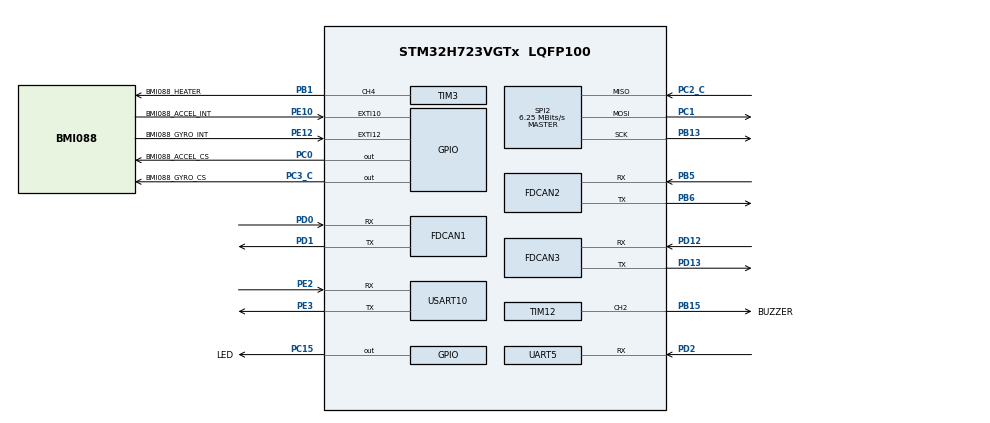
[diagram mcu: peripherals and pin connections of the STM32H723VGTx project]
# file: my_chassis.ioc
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CORTEX_M7.CPU_DCache=Disabled
CORTEX_M7.CPU_ICache=Enabled
CORTEX_M7.MPU_Control=__NULL
CORTEX_M7.default_mode_Activation=1
Dma.Request0=SPI2_TX
Dma.Request1=SPI2_RX
Dma.Request2=USART10_RX
Dma.Request3=USART10_TX
Dma.Request4=UART5_RX
Dma.SPI2_RX.1.Direction=DMA_PERIPH_TO_MEMORY
Dma.SPI2_RX.1.EventEnable=DISABLE
Dma.SPI2_RX.1.FIFOMode=DMA_FIFOMODE_DISABLE
Dma.SPI2_RX.1.Instance=DMA1_Stream1
Dma.SPI2_RX.1.MemDataAlignment=DMA_MDATAALIGN_BYTE
Dma.SPI2_RX.1.MemInc=DMA_MINC_ENABLE
Dma.SPI2_RX.1.Mode=DMA_NORMAL
Dma.SPI2_RX.1.PeriphDataAlignment=DMA_PDATAALIGN_BYTE
Dma.SPI2_RX.1.PeriphInc=DMA_PINC_DISABLE
Dma.SPI2_RX.1.Polarity=HAL_DMAMUX_REQ_GEN_RISING
Dma.SPI2_RX.1.Priority=DMA_PRIORITY_LOW
Dma.SPI2_RX.1.RequestNumber=1
Dma.SPI2_RX.1.SignalID=NONE
Dma.SPI2_RX.1.SyncEnable=DISABLE
Dma.SPI2_RX.1.SyncPolarity=HAL_DMAMUX_SYNC_NO_EVENT
Dma.SPI2_RX.1.SyncRequestNumber=1
Dma.SPI2_RX.1.SyncSignalID=NONE
Dma.SPI2_TX.0.Direction=DMA_MEMORY_TO_PERIPH
Dma.SPI2_TX.0.EventEnable=DISABLE
Dma.SPI2_TX.0.FIFOMode=DMA_FIFOMODE_DISABLE
Dma.SPI2_TX.0.Instance=DMA1_Stream0
Dma.SPI2_TX.0.MemDataAlignment=DMA_MDATAALIGN_BYTE
Dma.SPI2_TX.0.MemInc=DMA_MINC_ENABLE
Dma.SPI2_TX.0.Mode=DMA_NORMAL
Dma.SPI2_TX.0.PeriphDataAlignment=DMA_PDATAALIGN_BYTE
Dma.SPI2_TX.0.PeriphInc=DMA_PINC_DISABLE
Dma.SPI2_TX.0.Polarity=HAL_DMAMUX_REQ_GEN_RISING
Dma.SPI2_TX.0.Priority=DMA_PRIORITY_LOW
Dma.SPI2_TX.0.RequestNumber=1
Dma.SPI2_TX.0.SignalID=NONE
Dma.SPI2_TX.0.SyncEnable=DISABLE
Dma.SPI2_TX.0.SyncPolarity=HAL_DMAMUX_SYNC_NO_EVENT
Dma.SPI2_TX.0.SyncRequestNumber=1
Dma.SPI2_TX.0.SyncSignalID=NONE
Dma.UART5_RX.4.Direction=DMA_PERIPH_TO_MEMORY
Dma.UART5_RX.4.EventEnable=DISABLE
Dma.UART5_RX.4.FIFOMode=DMA_FIFOMODE_DISABLE
Dma.UART5_RX.4.Instance=DMA1_Stream4
Dma.UART5_RX.4.MemDataAlignment=DMA_MDATAALIGN_BYTE
Dma.UART5_RX.4.MemInc=DMA_MINC_ENABLE
Dma.UART5_RX.4.Mode=DMA_NORMAL
Dma.UART5_RX.4.PeriphDataAlignment=DMA_PDATAALIGN_BYTE
Dma.UART5_RX.4.PeriphInc=DMA_PINC_DISABLE
Dma.UART5_RX.4.Polarity=HAL_DMAMUX_REQ_GEN_RISING
Dma.UART5_RX.4.Priority=DMA_PRIORITY_LOW
Dma.UART5_RX.4.RequestNumber=1
Dma.UART5_RX.4.SignalID=NONE
Dma.UART5_RX.4.SyncEnable=DISABLE
Dma.UART5_RX.4.SyncPolarity=HAL_DMAMUX_SYNC_NO_EVENT
Dma.UART5_RX.4.SyncRequestNumber=1
Dma.UART5_RX.4.SyncSignalID=NONE
Dma.USART10_RX.2.Direction=DMA_PERIPH_TO_MEMORY
Dma.USART10_RX.2.EventEnable=DISABLE
Dma.USART10_RX.2.FIFOMode=DMA_FIFOMODE_DISABLE
Dma.USART10_RX.2.Instance=DMA1_Stream2
Dma.USART10_RX.2.MemDataAlignment=DMA_MDATAALIGN_BYTE
Dma.USART10_RX.2.MemInc=DMA_MINC_ENABLE
Dma.USART10_RX.2.Mode=DMA_NORMAL
Dma.USART10_RX.2.PeriphDataAlignment=DMA_PDATAALIGN_BYTE
Dma.USART10_RX.2.PeriphInc=DMA_PINC_DISABLE
Dma.USART10_RX.2.Polarity=HAL_DMAMUX_REQ_GEN_RISING
Dma.USART10_RX.2.Priority=DMA_PRIORITY_LOW
Dma.USART10_RX.2.RequestNumber=1
Dma.USART10_RX.2.SignalID=NONE
Dma.USART10_RX.2.SyncEnable=DISABLE
Dma.USART10_RX.2.SyncPolarity=HAL_DMAMUX_SYNC_NO_EVENT
Dma.USART10_RX.2.SyncRequestNumber=1
Dma.USART10_RX.2.SyncSignalID=NONE
Dma.USART10_TX.3.Direction=DMA_MEMORY_TO_PERIPH
Dma.USART10_TX.3.EventEnable=DISABLE
Dma.USART10_TX.3.FIFOMode=DMA_FIFOMODE_DISABLE
Dma.USART10_TX.3.Instance=DMA1_Stream3
Dma.USART10_TX.3.MemDataAlignment=DMA_MDATAALIGN_BYTE
Dma.USART10_TX.3.MemInc=DMA_MINC_ENABLE
Dma.USART10_TX.3.Mode=DMA_NORMAL
Dma.USART10_TX.3.PeriphDataAlignment=DMA_PDATAALIGN_BYTE
Dma.USART10_TX.3.PeriphInc=DMA_PINC_DISABLE
Dma.USART10_TX.3.Polarity=HAL_DMAMUX_REQ_GEN_RISING
Dma.USART10_TX.3.Priority=DMA_PRIORITY_LOW
Dma.USART10_TX.3.RequestNumber=1
Dma.USART10_TX.3.SignalID=NONE
Dma.USART10_TX.3.SyncEnable=DISABLE
Dma.USART10_TX.3.SyncPolarity=HAL_DMAMUX_SYNC_NO_EVENT
Dma.USART10_TX.3.SyncRequestNumber=1
Dma.USART10_TX.3.SyncSignalID=NONE
FDCAN1.AutoRetransmission=ENABLE
FDCAN1.CalculateBaudRateNominal=1000000
FDCAN1.CalculateTimeBitNominal=1000
FDCAN1.CalculateTimeQuantumNominal=50.0
FDCAN1.ExtFiltersNbr=1
FDCAN1.MessageRAMOffset=0
FDCAN1.NominalPrescaler=5
FDCAN1.NominalSyncJumpWidth=4
FDCAN1.NominalTimeSeg1=14
FDCAN1.NominalTimeSeg2=5
FDCAN1.RxFifo0ElmtsNbr=8
FDCAN1.StdFiltersNbr=1
FDCAN1.TxFifoQueueElmtsNbr=8
FDCAN2.AutoRetransmission=ENABLE
FDCAN2.CalculateBaudRateNominal=1000000
FDCAN2.CalculateTimeBitNominal=1000
FDCAN2.CalculateTimeQuantumNominal=50.0
FDCAN2.ExtFiltersNbr=1
FDCAN2.MessageRAMOffset=67
FDCAN2.NominalPrescaler=5
FDCAN2.NominalSyncJumpWidth=4
FDCAN2.NominalTimeSeg1=14
FDCAN2.NominalTimeSeg2=5
FDCAN2.RxFifo1ElmtsNbr=8
FDCAN2.StdFiltersNbr=1
FDCAN2.TxFifoQueueElmtsNbr=8
FDCAN3.AutoRetransmission=ENABLE
FDCAN3.CalculateBaudRateData=5000000
FDCAN3.CalculateBaudRateNominal=1000000
FDCAN3.CalculateTimeBitData=200
FDCAN3.CalculateTimeBitNominal=1000
FDCAN3.CalculateTimeQuantumData=10.0
FDCAN3.CalculateTimeQuantumNominal=50.0
FDCAN3.DataPrescaler=1
FDCAN3.DataSyncJumpWidth=4
FDCAN3.DataTimeSeg1=14
FDCAN3.DataTimeSeg2=5
FDCAN3.ExtFiltersNbr=1
FDCAN3.FrameFormat=FDCAN_FRAME_FD_BRS
FDCAN3.MessageRAMOffset=134
FDCAN3.NominalPrescaler=5
FDCAN3.NominalSyncJumpWidth=4
FDCAN3.NominalTimeSeg1=14
FDCAN3.NominalTimeSeg2=5
FDCAN3.RxFifo1ElmtSize=FDCAN_DATA_BYTES_64
FDCAN3.RxFifo1ElmtsNbr=64
FDCAN3.StdFiltersNbr=1
FDCAN3.TxElmtSize=FDCAN_DATA_BYTES_64
FDCAN3.TxFifoQueueElmtsNbr=8
FREERTOS.Tasks01=defaultTask,24,2048,StartDefaultTask,Default,NULL,Dynamic,NULL,NULL
FREERTOS.configTOTAL_HEAP_SIZE=64*1024
Mcu.Family=STM32H7
Mcu.Name=STM32H723VGTx
Mcu.Package=LQFP100
NVIC.DMA1_Stream0_IRQn=true\:5\:0\:false\:false\:true\:true\:false\:true\:true
NVIC.DMA1_Stream1_IRQn=true\:5\:0\:false\:false\:true\:true\:false\:true\:true
NVIC.DMA1_Stream2_IRQn=true\:5\:0\:false\:false\:true\:true\:false\:true\:true
NVIC.DMA1_Stream3_IRQn=true\:5\:0\:false\:false\:true\:true\:false\:true\:true
NVIC.DMA1_Stream4_IRQn=true\:5\:0\:false\:false\:true\:true\:false\:true\:true
NVIC.EXTI15_10_IRQn=true\:5\:0\:false\:false\:true\:true\:true\:true\:true
NVIC.FDCAN2_IT0_IRQn=true\:5\:0\:false\:false\:true\:true\:true\:true\:true
NVIC.FDCAN2_IT1_IRQn=true\:5\:0\:false\:false\:true\:true\:true\:true\:true
NVIC.FDCAN3_IT0_IRQn=true\:5\:0\:false\:false\:true\:true\:true\:true\:true
NVIC.PriorityGroup=NVIC_PRIORITYGROUP_4
NVIC.SPI2_IRQn=true\:5\:0\:false\:false\:true\:true\:false\:true\:true
NVIC.TIM6_DAC_IRQn=true\:0\:0\:false\:false\:true\:false\:false\:true\:true
NVIC.TimeBase=TIM6_DAC_IRQn
NVIC.TimeBaseIP=TIM6
NVIC.USART10_IRQn=true\:5\:0\:false\:false\:true\:true\:false\:true\:true
PA13(JTMS/SWDIO).Mode=Serial_Wire
PA13(JTMS/SWDIO).Signal=DEBUG_JTMS-SWDIO
PA14(JTCK/SWCLK).Mode=Serial_Wire
PA14(JTCK/SWCLK).Signal=DEBUG_JTCK-SWCLK
PB1.GPIO_Label=BMI088_HEATER
PB1.Signal=S_TIM3_CH4
PB13.Mode=Full_Duplex_Master
PB13.Signal=SPI2_SCK
PB15.GPIO_Label=BUZZER
PB15.Signal=S_TIM12_CH2
PB5.Mode=FDCAN_Activate
PB5.Signal=FDCAN2_RX
PB6.Mode=FDCAN_Activate
PB6.Signal=FDCAN2_TX
PC0.GPIO_Label=BMI088_ACCEL_CS
PC0.GPIO_Speed=GPIO_SPEED_FREQ_VERY_HIGH
PC0.PinState=GPIO_PIN_SET
PC0.Signal=GPIO_Output
PC1.Mode=Full_Duplex_Master
PC1.Signal=SPI2_MOSI
PC15-OSC32_OUT.GPIO_Label=LED
PC15-OSC32_OUT.PinState=GPIO_PIN_SET
PC15-OSC32_OUT.Signal=GPIO_Output
PC2_C.Mode=Full_Duplex_Master
PC2_C.Signal=SPI2_MISO
PC3_C.GPIO_Label=BMI088_GYRO_CS
PC3_C.GPIO_Speed=GPIO_SPEED_FREQ_VERY_HIGH
PC3_C.PinState=GPIO_PIN_SET
PC3_C.Signal=GPIO_Output
PD0.Mode=FDCAN_Activate
PD0.Signal=FDCAN1_RX
PD1.Mode=FDCAN_Activate
PD1.Signal=FDCAN1_TX
PD12.Mode=FDCAN_Activate
PD12.Signal=FDCAN3_RX
PD13.Mode=FDCAN_Activate
PD13.Signal=FDCAN3_TX
PD2.Mode=Asynchronous
PD2.Signal=UART5_RX
PE10.GPIO_Label=BMI088_ACCEL_INT
PE10.GPIO_ModeDefaultEXTI=GPIO_MODE_IT_FALLING
PE10.Signal=GPXTI10
PE12.GPIO_Label=BMI088_GYRO_INT
PE12.GPIO_ModeDefaultEXTI=GPIO_MODE_IT_FALLING
PE12.Signal=GPXTI12
PE2.Mode=Asynchronous
PE2.Signal=USART10_RX
PE3.Mode=Asynchronous
PE3.Signal=USART10_TX
PH0-OSC_IN.Mode=HSE-External-Oscillator
PH0-OSC_IN.Signal=RCC_OSC_IN
PH1-OSC_OUT.Mode=HSE-External-Oscillator
PH1-OSC_OUT.Signal=RCC_OSC_OUT
ProjectManager.HeapSize=0x1000
ProjectManager.StackSize=0x1000
ProjectManager.TargetToolchain=CMake
RCC.ADCFreq_Value=100000000
RCC.APB1Freq_Value=137500000
RCC.APB2Freq_Value=137500000
RCC.APB3Freq_Value=137500000
RCC.APB4Freq_Value=137500000
RCC.CortexFreq_Value=550000000
RCC.D1PPRE=RCC_APB3_DIV2
RCC.D2PPRE1=RCC_APB1_DIV2
RCC.D2PPRE2=RCC_APB2_DIV2
RCC.D3PPRE=RCC_APB4_DIV2
RCC.DIVM1=3
RCC.DIVM2=24
RCC.DIVN1=68
RCC.DIVN2=200
RCC.DIVP1=1
RCC.DIVQ1=3
RCC.FDCANCLockSelection=RCC_FDCANCLKSOURCE_PLL2
RCC.HCLKFreq_Value=275000000
RCC.HPRE=RCC_HCLK_DIV2
RCC.HSE_VALUE=24000000
RCC.PLLFRACN=6144
RCC.PLLSourceVirtual=RCC_PLLSOURCE_HSE
RCC.SPI123CLockSelection=RCC_SPI123CLKSOURCE_PLL2
RCC.SYSCLKFreq_VALUE=550000000
RCC.SYSCLKSource=RCC_SYSCLKSOURCE_PLLCLK
RCC.USBFreq_Value=183333333.33333334
SH.S_TIM12_CH2.0=TIM12_CH2,PWM Generation2 CH2
SH.S_TIM3_CH4.0=TIM3_CH4,PWM Generation4 CH4
SPI2.BaudRatePrescaler=SPI_BAUDRATEPRESCALER_16
SPI2.CalculateBaudRate=6.25 MBits/s
SPI2.DataSize=SPI_DATASIZE_8BIT
SPI2.Direction=SPI_DIRECTION_2LINES
SPI2.Mode=SPI_MODE_MASTER
SPI2.VirtualType=VM_MASTER
TIM12.Channel-PWM\ Generation2\ CH2=TIM_CHANNEL_2
TIM12.Period=5499
TIM12.Prescaler=99
TIM3.Channel-PWM\ Generation4\ CH4=TIM_CHANNEL_4
TIM3.Period=5499
TIM3.Prescaler=99
UART5.BaudRate=100000
UART5.Parity=PARITY_EVEN
UART5.StopBits=UART_STOPBITS_2
UART5.WordLength=WORDLENGTH_9B
USART10.VirtualMode=VM_ASYNC
VP_FREERTOS_VS_CMSIS_V2.Mode=CMSIS_V2
VP_MEMORYMAP_VS_MEMORYMAP.Mode=CurAppReg
VP_SYS_VS_tim6.Mode=TIM6
board=custom

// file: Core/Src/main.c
/* USER CODE BEGIN Header */
/**
  ******************************************************************************
  * @file           : main.c
  * @brief          : Main program body
  ******************************************************************************
  * @attention
  *
  * Copyright (c) 2026 STMicroelectronics.
  * All rights reserved.
  *
  * This software is licensed under terms that can be found in the LICENSE file
  * in the root directory of this software component.
  * If no LICENSE file comes with this software, it is provided AS-IS.
  *
  ******************************************************************************
  */
/* USER CODE END Header */
#include "main.h"
#include "FreeRTOS.h"
#include "cmsis_os2.h"
#include "dma.h"
#include "fdcan.h"
#include "spi.h"
#include "tim.h"
#include "usart.h"
#include "gpio.h"

void SystemClock_Config(void);
void PeriphCommonClock_Config(void);
void MX_FREERTOS_Init(void);

int main(void)
{

  /* Enable the CPU Cache */

  /* Enable I-Cache---------------------------------------------------------*/
  SCB_EnableICache();

  /* MCU Configuration--------------------------------------------------------*/

  /* Reset of all peripherals, Initializes the Flash interface and the Systick. */
  HAL_Init();

  /* Configure the system clock */
  SystemClock_Config();

  /* Configure the peripherals common clocks */
  PeriphCommonClock_Config();

  /* Initialize all configured peripherals */
  MX_GPIO_Init();
  MX_DMA_Init();
  MX_SPI2_Init();
  MX_FDCAN1_Init();
  MX_FDCAN2_Init();
  MX_FDCAN3_Init();
  MX_TIM3_Init();
  MX_TIM12_Init();
  MX_USART10_UART_Init();
  MX_UART5_Init();

  /* Init scheduler */
  osKernelInitialize();  /* Call init function for freertos objects (in cmsis_os2.c) */
  MX_FREERTOS_Init();

  /* Start scheduler */
  osKernelStart();

  /* We should never get here as control is now taken by the scheduler */

  /* Infinite loop */
  while (1)
  {

  }
}

void SystemClock_Config(void)
{
  RCC_OscInitTypeDef RCC_OscInitStruct = {0};
  RCC_ClkInitTypeDef RCC_ClkInitStruct = {0};

  /** Supply configuration update enable
  */
  HAL_PWREx_ConfigSupply(PWR_LDO_SUPPLY);

  /** Configure the main internal regulator output voltage
  */
  __HAL_PWR_VOLTAGESCALING_CONFIG(PWR_REGULATOR_VOLTAGE_SCALE0);

  while(!__HAL_PWR_GET_FLAG(PWR_FLAG_VOSRDY)) {}

  /** Initializes the RCC Oscillators according to the specified parameters
  * in the RCC_OscInitTypeDef structure.
  */
  RCC_OscInitStruct.OscillatorType = RCC_OSCILLATORTYPE_HSE;
  RCC_OscInitStruct.HSEState = RCC_HSE_ON;
  RCC_OscInitStruct.PLL.PLLState = RCC_PLL_ON;
  RCC_OscInitStruct.PLL.PLLSource = RCC_PLLSOURCE_HSE;
  RCC_OscInitStruct.PLL.PLLM = 3;
  RCC_OscInitStruct.PLL.PLLN = 68;
  RCC_OscInitStruct.PLL.PLLP = 1;
  RCC_OscInitStruct.PLL.PLLQ = 3;
  RCC_OscInitStruct.PLL.PLLR = 2;
  RCC_OscInitStruct.PLL.PLLRGE = RCC_PLL1VCIRANGE_3;
  RCC_OscInitStruct.PLL.PLLVCOSEL = RCC_PLL1VCOWIDE;
  RCC_OscInitStruct.PLL.PLLFRACN = 6144;
  if (HAL_RCC_OscConfig(&RCC_OscInitStruct) != HAL_OK)
  {
    Error_Handler();
  }

  /** Initializes the CPU, AHB and APB buses clocks
  */
  RCC_ClkInitStruct.ClockType = RCC_CLOCKTYPE_HCLK|RCC_CLOCKTYPE_SYSCLK
                              |RCC_CLOCKTYPE_PCLK1|RCC_CLOCKTYPE_PCLK2
                              |RCC_CLOCKTYPE_D3PCLK1|RCC_CLOCKTYPE_D1PCLK1;
  RCC_ClkInitStruct.SYSCLKSource = RCC_SYSCLKSOURCE_PLLCLK;
  RCC_ClkInitStruct.SYSCLKDivider = RCC_SYSCLK_DIV1;
  RCC_ClkInitStruct.AHBCLKDivider = RCC_HCLK_DIV2;
  RCC_ClkInitStruct.APB3CLKDivider = RCC_APB3_DIV2;
  RCC_ClkInitStruct.APB1CLKDivider = RCC_APB1_DIV2;
  RCC_ClkInitStruct.APB2CLKDivider = RCC_APB2_DIV2;
  RCC_ClkInitStruct.APB4CLKDivider = RCC_APB4_DIV2;

  if (HAL_RCC_ClockConfig(&RCC_ClkInitStruct, FLASH_LATENCY_3) != HAL_OK)
  {
    Error_Handler();
  }
}

void PeriphCommonClock_Config(void)
{
  RCC_PeriphCLKInitTypeDef PeriphClkInitStruct = {0};

  /** Initializes the peripherals clock
  */
  PeriphClkInitStruct.PeriphClockSelection = RCC_PERIPHCLK_SPI2|RCC_PERIPHCLK_FDCAN;
  PeriphClkInitStruct.PLL2.PLL2M = 24;
  PeriphClkInitStruct.PLL2.PLL2N = 200;
  PeriphClkInitStruct.PLL2.PLL2P = 2;
  PeriphClkInitStruct.PLL2.PLL2Q = 2;
  PeriphClkInitStruct.PLL2.PLL2R = 2;
  PeriphClkInitStruct.PLL2.PLL2RGE = RCC_PLL2VCIRANGE_0;
  PeriphClkInitStruct.PLL2.PLL2VCOSEL = RCC_PLL2VCOMEDIUM;
  PeriphClkInitStruct.PLL2.PLL2FRACN = 0;
  PeriphClkInitStruct.Spi123ClockSelection = RCC_SPI123CLKSOURCE_PLL2;
  PeriphClkInitStruct.FdcanClockSelection = RCC_FDCANCLKSOURCE_PLL2;
  if (HAL_RCCEx_PeriphCLKConfig(&PeriphClkInitStruct) != HAL_OK)
  {
    Error_Handler();
  }
}

void HAL_TIM_PeriodElapsedCallback(TIM_HandleTypeDef *htim)
{
  if (htim->Instance == TIM6)
  {
    HAL_IncTick();
  }
}

void Error_Handler(void)
{
  __disable_irq();
  while (1)
  {
  }
}

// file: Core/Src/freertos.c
/* USER CODE BEGIN Header */
/**
  ******************************************************************************
  * File Name          : freertos.c
  * Description        : Code for freertos applications
  ******************************************************************************
  * @attention
  *
  * Copyright (c) 2026 STMicroelectronics.
  * All rights reserved.
  *
  * This software is licensed under terms that can be found in the LICENSE file
  * in the root directory of this software component.
  * If no LICENSE file comes with this software, it is provided AS-IS.
  *
  ******************************************************************************
  */
/* USER CODE END Header */

#include "FreeRTOS.h"
#include "task.h"
#include "main.h"
#include "FreeRTOS.h"
#include "cmsis_os2.h"

/* USER CODE BEGIN Includes */
#include "app_main.h"
/* USER CODE END Includes */

/* Definitions for defaultTask */
osThreadId_t defaultTaskHandle;
const osThreadAttr_t defaultTask_attributes = {
  .name = "defaultTask",
  .stack_size = 2048 * 4,
  .priority = (osPriority_t) osPriorityNormal,
};

void StartDefaultTask(void *argument);

void MX_FREERTOS_Init(void); /* (MISRA C 2004 rule 8.1) */

void MX_FREERTOS_Init(void) {

  /* Create the thread(s) */
  /* creation of defaultTask */
  defaultTaskHandle = osThreadNew(StartDefaultTask, NULL, &defaultTask_attributes);

}

void StartDefaultTask(void *argument)
{
  /* USER CODE BEGIN StartDefaultTask */
  app_main();

  /* 正常情况下 app_main()/XROBOT_MAIN() 不会返回 */
  for (;;)
  {
    osDelay(1000);
  }
  /* USER CODE END StartDefaultTask */
}
